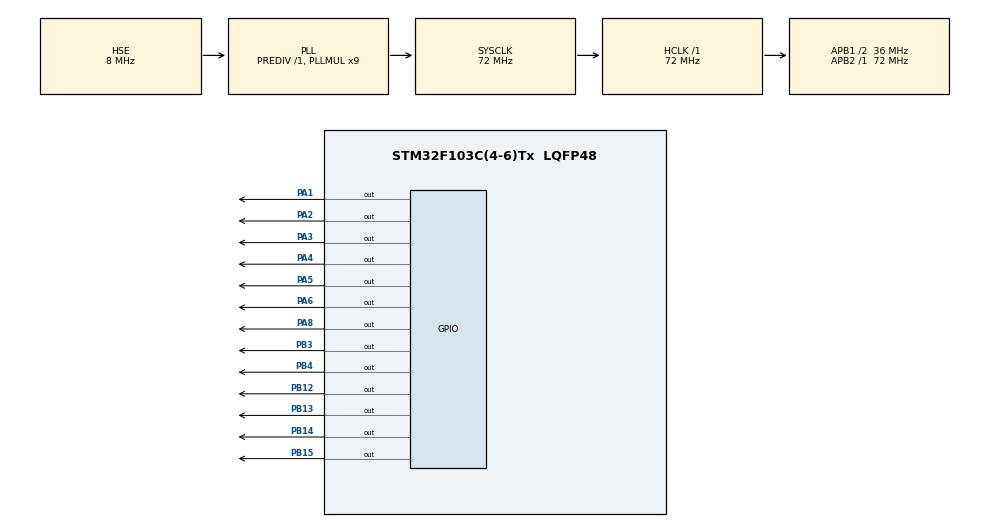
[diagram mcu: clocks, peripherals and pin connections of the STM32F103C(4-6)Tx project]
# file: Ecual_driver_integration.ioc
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Mcu.Family=STM32F1
Mcu.Name=STM32F103C(4-6)Tx
Mcu.Package=LQFP48
NVIC.PriorityGroup=NVIC_PRIORITYGROUP_4
PA1.Signal=GPIO_Output
PA13.Mode=Serial_Wire
PA13.Signal=SYS_JTMS-SWDIO
PA14.Mode=Serial_Wire
PA14.Signal=SYS_JTCK-SWCLK
PA2.Signal=GPIO_Output
PA3.Signal=GPIO_Output
PA4.Signal=GPIO_Output
PA5.Signal=GPIO_Output
PA6.Signal=GPIO_Output
PA8.Signal=GPIO_Output
PB12.Signal=GPIO_Output
PB13.Signal=GPIO_Output
PB14.Signal=GPIO_Output
PB15.Signal=GPIO_Output
PB3.Signal=GPIO_Output
PB4.Signal=GPIO_Output
PD0-OSC_IN.Mode=HSE-External-Oscillator
PD0-OSC_IN.Signal=RCC_OSC_IN
PD1-OSC_OUT.Mode=HSE-External-Oscillator
PD1-OSC_OUT.Signal=RCC_OSC_OUT
ProjectManager.HeapSize=0x200
ProjectManager.StackSize=0x400
ProjectManager.TargetToolchain=STM32CubeIDE
RCC.AHBFreq_Value=72000000
RCC.APB1CLKDivider=RCC_HCLK_DIV2
RCC.APB1Freq_Value=36000000
RCC.APB1TimFreq_Value=72000000
RCC.APB2Freq_Value=72000000
RCC.APB2TimFreq_Value=72000000
RCC.HCLKFreq_Value=72000000
RCC.PLLMUL=RCC_PLL_MUL9
RCC.PLLSourceVirtual=RCC_PLLSOURCE_HSE
RCC.SYSCLKFreq_VALUE=72000000
RCC.SYSCLKSource=RCC_SYSCLKSOURCE_PLLCLK
RCC.USBFreq_Value=72000000
TIM2.Period=0
VP_TIM2_VS_ClockSourceINT.Mode=Internal
board=custom

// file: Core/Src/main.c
/* USER CODE BEGIN Header */
/**
  ******************************************************************************
  * @file           : main.c
  * @brief          : Main program body
  ******************************************************************************
  * @attention
  *
  * Copyright (c) 2025 STMicroelectronics.
  * All rights reserved.
  *
  * This software is licensed under terms that can be found in the LICENSE file
  * in the root directory of this software component.
  * If no LICENSE file comes with this software, it is provided AS-IS.
  *
  ******************************************************************************
  */
/* USER CODE END Header */
#include "main.h"
#include "../../ECUAL/LCD16x2.h"

#define MyLCD LCD16X2_1

TIM_HandleTypeDef htim2;

void SystemClock_Config(void);
static void MX_GPIO_Init(void);
static void MX_TIM2_Init(void);

int main(void)
{

  /* MCU Configuration--------------------------------------------------------*/

  /* Reset of all peripherals, Initializes the Flash interface and the Systick. */
  HAL_Init();

  /* Configure the system clock */
  SystemClock_Config();

  /* Initialize all configured peripherals */
  MX_GPIO_Init();
  MX_TIM2_Init();
  /* USER CODE BEGIN 2 */
  //TimerDelay_Init();
  /* USER CODE END 2 */

  LCD16X2_Init(MyLCD);
  LCD16X2_Clear(MyLCD);
  LCD16X2_Set_Cursor(MyLCD, 1, 1);
  LCD16X2_Write_String(MyLCD, "  DeepBlue");
  LCD16X2_Set_Cursor(MyLCD, 2, 1);
  LCD16X2_Write_String(MyLCD, "STM32 Course");

  HAL_Delay(500);

  /* Infinite loop */
  while (1)
  {

  }
}

void SystemClock_Config(void)
{
  RCC_OscInitTypeDef RCC_OscInitStruct = {0};
  RCC_ClkInitTypeDef RCC_ClkInitStruct = {0};

  /** Initializes the RCC Oscillators according to the specified parameters
  * in the RCC_OscInitTypeDef structure.
  */
  RCC_OscInitStruct.OscillatorType = RCC_OSCILLATORTYPE_HSE;
  RCC_OscInitStruct.HSEState = RCC_HSE_ON;
  RCC_OscInitStruct.HSEPredivValue = RCC_HSE_PREDIV_DIV1;
  RCC_OscInitStruct.HSIState = RCC_HSI_ON;
  RCC_OscInitStruct.PLL.PLLState = RCC_PLL_ON;
  RCC_OscInitStruct.PLL.PLLSource = RCC_PLLSOURCE_HSE;
  RCC_OscInitStruct.PLL.PLLMUL = RCC_PLL_MUL9;
  if (HAL_RCC_OscConfig(&RCC_OscInitStruct) != HAL_OK)
  {
    Error_Handler();
  }

  /** Initializes the CPU, AHB and APB buses clocks
  */
  RCC_ClkInitStruct.ClockType = RCC_CLOCKTYPE_HCLK|RCC_CLOCKTYPE_SYSCLK
                              |RCC_CLOCKTYPE_PCLK1|RCC_CLOCKTYPE_PCLK2;
  RCC_ClkInitStruct.SYSCLKSource = RCC_SYSCLKSOURCE_PLLCLK;
  RCC_ClkInitStruct.AHBCLKDivider = RCC_SYSCLK_DIV1;
  RCC_ClkInitStruct.APB1CLKDivider = RCC_HCLK_DIV2;
  RCC_ClkInitStruct.APB2CLKDivider = RCC_HCLK_DIV1;

  if (HAL_RCC_ClockConfig(&RCC_ClkInitStruct, FLASH_LATENCY_2) != HAL_OK)
  {
    Error_Handler();
  }
}

static void MX_TIM2_Init(void)
{

  TIM_ClockConfigTypeDef sClockSourceConfig = {0};
  TIM_MasterConfigTypeDef sMasterConfig = {0};

  htim2.Instance = TIM2;
  htim2.Init.Prescaler = 0;
  htim2.Init.CounterMode = TIM_COUNTERMODE_UP;
  htim2.Init.Period = 0;
  htim2.Init.ClockDivision = TIM_CLOCKDIVISION_DIV1;
  htim2.Init.AutoReloadPreload = TIM_AUTORELOAD_PRELOAD_DISABLE;
  if (HAL_TIM_Base_Init(&htim2) != HAL_OK)
  {
    Error_Handler();
  }
  sClockSourceConfig.ClockSource = TIM_CLOCKSOURCE_INTERNAL;
  if (HAL_TIM_ConfigClockSource(&htim2, &sClockSourceConfig) != HAL_OK)
  {
    Error_Handler();
  }
  sMasterConfig.MasterOutputTrigger = TIM_TRGO_RESET;
  sMasterConfig.MasterSlaveMode = TIM_MASTERSLAVEMODE_DISABLE;
  if (HAL_TIMEx_MasterConfigSynchronization(&htim2, &sMasterConfig) != HAL_OK)
  {
    Error_Handler();
  }

}

static void MX_GPIO_Init(void)
{
  GPIO_InitTypeDef GPIO_InitStruct = {0};

  /* GPIO Ports Clock Enable */
  __HAL_RCC_GPIOD_CLK_ENABLE();
  __HAL_RCC_GPIOA_CLK_ENABLE();
  __HAL_RCC_GPIOB_CLK_ENABLE();

  /*Configure GPIO pin Output Level */
  HAL_GPIO_WritePin(GPIOA, GPIO_PIN_1|GPIO_PIN_2|GPIO_PIN_3|GPIO_PIN_4
                          |GPIO_PIN_5|GPIO_PIN_6|GPIO_PIN_8, GPIO_PIN_RESET);

  /*Configure GPIO pin Output Level */
  HAL_GPIO_WritePin(GPIOB, GPIO_PIN_12|GPIO_PIN_13|GPIO_PIN_14|GPIO_PIN_15
                          |GPIO_PIN_3|GPIO_PIN_4, GPIO_PIN_RESET);

  /*Configure GPIO pins : PA1 PA2 PA3 PA4
                           PA5 PA6 PA8 */
  GPIO_InitStruct.Pin = GPIO_PIN_1|GPIO_PIN_2|GPIO_PIN_3|GPIO_PIN_4
                          |GPIO_PIN_5|GPIO_PIN_6|GPIO_PIN_8;
  GPIO_InitStruct.Mode = GPIO_MODE_OUTPUT_PP;
  GPIO_InitStruct.Pull = GPIO_NOPULL;
  GPIO_InitStruct.Speed = GPIO_SPEED_FREQ_LOW;
  HAL_GPIO_Init(GPIOA, &GPIO_InitStruct);

  /*Configure GPIO pins : PB12 PB13 PB14 PB15
                           PB3 PB4 */
  GPIO_InitStruct.Pin = GPIO_PIN_12|GPIO_PIN_13|GPIO_PIN_14|GPIO_PIN_15
                          |GPIO_PIN_3|GPIO_PIN_4;
  GPIO_InitStruct.Mode = GPIO_MODE_OUTPUT_PP;
  GPIO_InitStruct.Pull = GPIO_NOPULL;
  GPIO_InitStruct.Speed = GPIO_SPEED_FREQ_LOW;
  HAL_GPIO_Init(GPIOB, &GPIO_InitStruct);

}

void Error_Handler(void)
{
  __disable_irq();
  while (1)
  {
  }
}
